# ATSAMC21G17A register map
Vendor: Microchip Technology; Series: SAMC21; File version: 0
CPU: CM0+ r0p0, selectable endian, MPU, no FPU, 2 interrupt priority bits
Registers are 32-bit, read-write, reset 0x0 unless marked. A register's access mark holds for its fields unless they carry their own. Offsets are from the block's base; [hi:lo] are bit positions; {n}, {i} and the like mark numbered series; 'fields as' and 'values as' point back to an identical list.

## EIC — External Interrupt Controller
Base 0x40002800; register names take the prefix EIC_
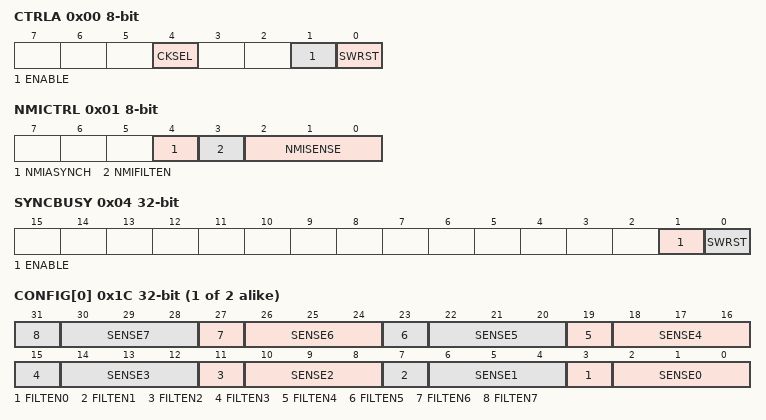
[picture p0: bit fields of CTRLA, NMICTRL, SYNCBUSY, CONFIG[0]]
0x00 CTRLA 8-bit — Control
  [4] CKSEL — Clock Selection
    0=CLK_GCLK (Clocked by GCLK); 1=CLK_ULP32K (Clocked by ULP32K)
  [1] ENABLE
  [0] SWRST — Software Reset
0x01 NMICTRL 8-bit — NMI Control
  [4] NMIASYNCH — NMI Asynchronous edge Detection Enable
    0=SYNC (Edge detection is clock synchronously operated); 1=ASYNC (Edge detection is clock asynchronously operated)
  [3] NMIFILTEN — NMI Filter Enable
  [2:0] NMISENSE — NMI Input Sense Configuration
    0=NONE (No detection); 1=RISE (Rising-edge detection); 2=FALL (Falling-edge detection); 3=BOTH (Both-edges detection); 4=HIGH (High-level detection); 5=LOW (Low-level detection)
0x02 NMIFLAG 16-bit — NMI Interrupt Flag
  [0] NMI write-1-clears
0x04 SYNCBUSY ro
  [1] ENABLE — Enable synchronisation
  [0] SWRST — Software reset synchronisation
0x08 EVCTRL — Event Control
  [15:0] EXTINTEO — External Interrupt Event Output Enable
0x0C INTENCLR — Interrupt Enable Clear
  [15:0] EXTINT write-1-clears — External Interrupt Disable
0x10 INTENSET — Interrupt Enable Set
  [15:0] EXTINT write-1-sets — External Interrupt Enable
0x14 INTFLAG — Interrupt Flag Status and Clear
  [15:0] EXTINT write-1-clears — External Interrupt Flag
0x18 ASYNCH — EIC Asynchronous edge Detection Enable
  [15:0] ASYNCH
    values as NMICTRL.NMIASYNCH
{0x1C+4i} CONFIG[{i}] (i=0..1) — Configuration n
  [4n+3] FILTEN{n} (n=0..7) — Filter Enable {n}
  [4n+2:4n] SENSE{n} (n=0..7) — Input Sense Configuration {n}
    0=NONE (No detection); 1=RISE (Rising edge detection); 2=FALL (Falling edge detection); 3=BOTH (Both edges detection); 4=HIGH (High level detection); 5=LOW (Low level detection)

## EVSYS — Event System Interface
Base 0x42000000; register names take the prefix EVSYS_
0x00 CTRLA 8-bit — Control
  [0] SWRST — Software Reset
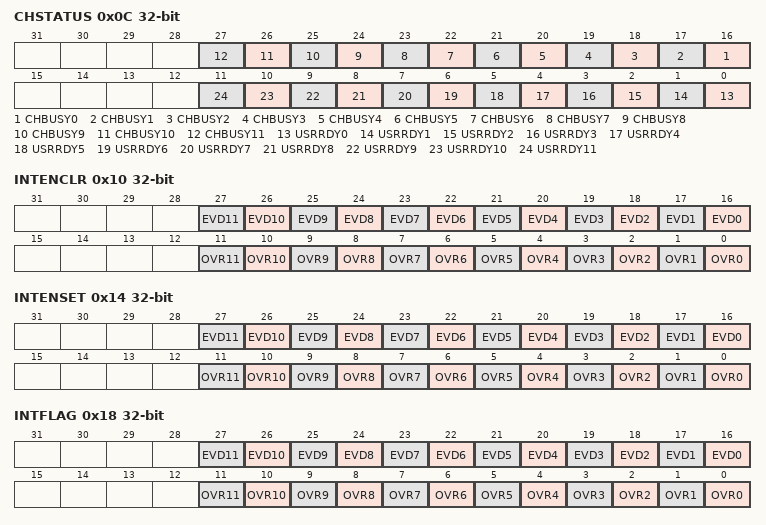
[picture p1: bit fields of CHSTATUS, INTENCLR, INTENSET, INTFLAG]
0x0C CHSTATUS ro — Channel Status
  [n+16] CHBUSY{n} (n=0..11) — Channel {n} Busy
  [n] USRRDY{n} (n=0..11) — Channel {n} User Ready
0x10 INTENCLR — Interrupt Enable Clear
  [n+16] EVD{n} (n=0..11) — Channel {n} Event Detection Interrupt Enable
  [n] OVR{n} (n=0..11) — Channel {n} Overrun Interrupt Enable
0x14 INTENSET — Interrupt Enable Set
  fields as INTENCLR
0x18 INTFLAG — Interrupt Flag Status and Clear
  [n+16] EVD{n} write-1-clears (n=0..11) — Channel {n} Event Detection
  [n] OVR{n} write-1-clears (n=0..11) — Channel {n} Overrun
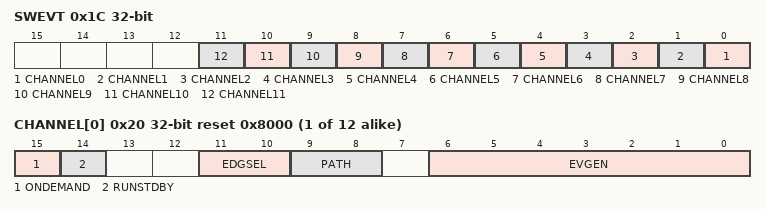
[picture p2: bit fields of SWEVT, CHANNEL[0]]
0x1C SWEVT wo — Software Event
  [n] CHANNEL{n} (n=0..11) — Channel {n} Software Selection
{0x20+4i} CHANNEL[{i}] (i=0..11) reset 0x8000 — Channel n
  [15] ONDEMAND — Generic Clock On Demand
  [14] RUNSTDBY — Run in standby
  [11:10] EDGSEL — Edge Detection Selection
    0=NO_EVT_OUTPUT (No event output when using the resynchronized or synchronous path); 1=RISING_EDGE (Event detection only on the rising edge of the signal from the event generator when using the resynchronized or synchronous path); 2=FALLING_EDGE (Event detection only on the falling edge of the signal from the event generator when using the resynchronized or synchronous path); 3=BOTH_EDGES (Event detection on rising and falling edges of the signal from the event generator when using the resynchronized or synchronous path)
  [9:8] PATH — Path Selection
    0=SYNCHRONOUS (Synchronous path); 1=RESYNCHRONIZED (Resynchronized path); 2=ASYNCHRONOUS (Asynchronous path)
  [6:0] EVGEN — Event Generator Selection
{0x80+4i} USER[{i}] (i=0..46) — User Multiplexer n
  [4:0] CHANNEL — Channel Event Selection

## FREQM — Frequency Meter
Base 0x40002C00; register names take the prefix FREQM_
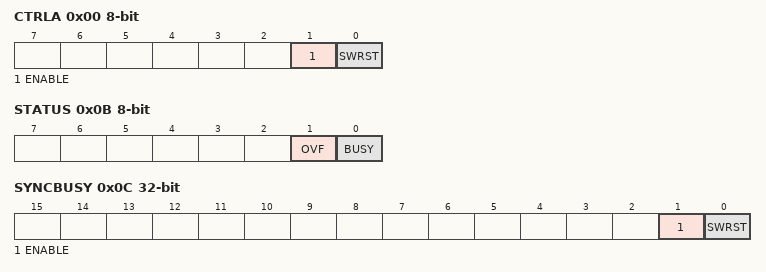
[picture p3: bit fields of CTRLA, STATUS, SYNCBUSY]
0x00 CTRLA 8-bit — Control A Register
  [1] ENABLE
  [0] SWRST — Software Reset
0x01 CTRLB 8-bit wo — Control B Register
  [0] START — Start Measurement
0x02 CFGA 16-bit — Config A register
  [7:0] REFNUM — Number of Reference Clock Cycles
0x08 INTENCLR 8-bit — Interrupt Enable Clear Register
  [0] DONE — Measurement Done Interrupt Enable
0x09 INTENSET 8-bit — Interrupt Enable Set Register
  [0] DONE — Measurement Done Interrupt Enable
0x0A INTFLAG 8-bit — Interrupt Flag Register
  [0] DONE write-1-clears — Measurement Done
0x0B STATUS 8-bit
  [1] OVF write-1-clears — Sticky Count Value Overflow
  [0] BUSY ro — FREQM Status
0x0C SYNCBUSY ro — Synchronization Busy Register
  [1] ENABLE
  [0] SWRST — Software Reset
0x10 VALUE ro — Count Value Register
  [23:0] VALUE — Measurement Value

## Notices in the file
Copyright (c) 2017 Microchip Technology Inc.
SPDX-License-Identifier: Apache-2.0
Licensed under the Apache License, Version 2.0 (the "License");
you may not use this file except in compliance with the License.
You may obtain a copy of the License at
http://www.apache.org/licenses/LICENSE-2.0
Unless required by applicable law or agreed to in writing, software
distributed under the License is distributed on an "AS IS" BASIS,
WITHOUT WARRANTIES OR CONDITIONS OF ANY KIND, either express or implied.
See the License for the specific language governing permissions and
limitations under the License.
